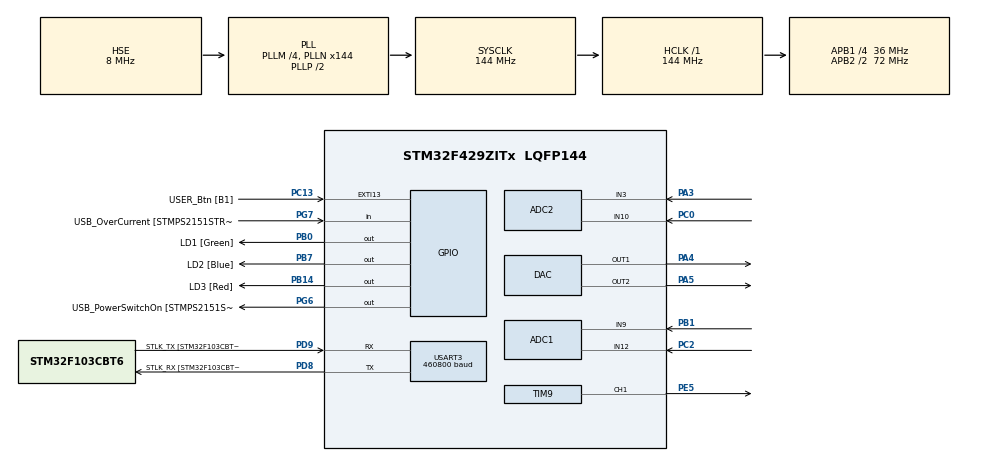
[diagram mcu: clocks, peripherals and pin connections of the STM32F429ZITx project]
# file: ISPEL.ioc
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ADC1.Channel-0\#ChannelRegularConversion=ADC_CHANNEL_9
ADC1.DMAAccessMode=ADC_DMAACCESSMODE_2
ADC1.DMAContinuousRequests=ENABLE
ADC1.EOCSelection=ADC_EOC_SEQ_CONV
ADC1.ExternalTrigConv=ADC_EXTERNALTRIGCONV_T3_TRGO
ADC1.Mode=ADC_DUALMODE_REGSIMULT
ADC1.NbrOfConversionFlag=1
ADC1.Rank-0\#ChannelRegularConversion=1
ADC1.SamplingTime-0\#ChannelRegularConversion=ADC_SAMPLETIME_3CYCLES
ADC1.master=1
ADC2.Channel-0\#ChannelRegularConversion=ADC_CHANNEL_3
ADC2.DMAAccessMode=ADC_DMAACCESSMODE_2
ADC2.DMAContinuousRequests=ENABLE
ADC2.EOCSelection=ADC_EOC_SEQ_CONV
ADC2.Mode=ADC_DUALMODE_REGSIMULT
ADC2.NbrOfConversionFlag=1
ADC2.Rank-0\#ChannelRegularConversion=1
ADC2.SamplingTime-0\#ChannelRegularConversion=ADC_SAMPLETIME_3CYCLES
DAC.DAC_Trigger=DAC_TRIGGER_T4_TRGO
DAC.DAC_Trigger2=DAC_TRIGGER_T2_TRGO
Dma.ADC1.0.Direction=DMA_PERIPH_TO_MEMORY
Dma.ADC1.0.FIFOMode=DMA_FIFOMODE_DISABLE
Dma.ADC1.0.Instance=DMA2_Stream0
Dma.ADC1.0.MemDataAlignment=DMA_MDATAALIGN_WORD
Dma.ADC1.0.MemInc=DMA_MINC_ENABLE
Dma.ADC1.0.Mode=DMA_CIRCULAR
Dma.ADC1.0.PeriphDataAlignment=DMA_PDATAALIGN_WORD
Dma.ADC1.0.PeriphInc=DMA_PINC_DISABLE
Dma.ADC1.0.Priority=DMA_PRIORITY_HIGH
Dma.ADC2.1.Direction=DMA_PERIPH_TO_MEMORY
Dma.ADC2.1.FIFOMode=DMA_FIFOMODE_DISABLE
Dma.ADC2.1.Instance=DMA2_Stream2
Dma.ADC2.1.MemDataAlignment=DMA_MDATAALIGN_WORD
Dma.ADC2.1.MemInc=DMA_MINC_ENABLE
Dma.ADC2.1.Mode=DMA_CIRCULAR
Dma.ADC2.1.PeriphDataAlignment=DMA_PDATAALIGN_WORD
Dma.ADC2.1.PeriphInc=DMA_PINC_DISABLE
Dma.ADC2.1.Priority=DMA_PRIORITY_HIGH
Dma.DAC1.2.Direction=DMA_MEMORY_TO_PERIPH
Dma.DAC1.2.FIFOMode=DMA_FIFOMODE_DISABLE
Dma.DAC1.2.Instance=DMA1_Stream5
Dma.DAC1.2.MemDataAlignment=DMA_MDATAALIGN_WORD
Dma.DAC1.2.MemInc=DMA_MINC_ENABLE
Dma.DAC1.2.Mode=DMA_CIRCULAR
Dma.DAC1.2.PeriphDataAlignment=DMA_PDATAALIGN_WORD
Dma.DAC1.2.PeriphInc=DMA_PINC_DISABLE
Dma.DAC1.2.Priority=DMA_PRIORITY_VERY_HIGH
Dma.DAC2.3.Direction=DMA_MEMORY_TO_PERIPH
Dma.DAC2.3.FIFOMode=DMA_FIFOMODE_DISABLE
Dma.DAC2.3.Instance=DMA1_Stream6
Dma.DAC2.3.MemDataAlignment=DMA_MDATAALIGN_WORD
Dma.DAC2.3.MemInc=DMA_MINC_ENABLE
Dma.DAC2.3.Mode=DMA_CIRCULAR
Dma.DAC2.3.PeriphDataAlignment=DMA_PDATAALIGN_WORD
Dma.DAC2.3.PeriphInc=DMA_PINC_DISABLE
Dma.DAC2.3.Priority=DMA_PRIORITY_VERY_HIGH
Dma.Request0=ADC1
Dma.Request1=ADC2
Dma.Request2=DAC1
Dma.Request3=DAC2
FREERTOS.INCLUDE_vTaskDelayUntil=1
FREERTOS.Tasks01=defaultTask,0,128,StartDefaultTask,Default,NULL,Dynamic,NULL,NULL
FREERTOS.configUSE_NEWLIB_REENTRANT=1
FREERTOS.configUSE_TIMERS=0
Mcu.Family=STM32F4
Mcu.Name=STM32F429ZITx
Mcu.Package=LQFP144
NVIC.ADC_IRQn=true\:5\:0\:false\:false\:true\:true\:true\:true\:true
NVIC.DMA1_Stream5_IRQn=true\:5\:0\:false\:false\:true\:true\:false\:true\:true
NVIC.DMA1_Stream6_IRQn=true\:5\:0\:false\:false\:true\:true\:false\:true\:true
NVIC.DMA2_Stream0_IRQn=true\:5\:0\:false\:false\:true\:true\:false\:true\:true
NVIC.DMA2_Stream2_IRQn=true\:5\:0\:false\:false\:true\:true\:false\:true\:true
NVIC.EXTI15_10_IRQn=true\:5\:0\:true\:false\:true\:true\:true\:true\:true
NVIC.PriorityGroup=NVIC_PRIORITYGROUP_4
NVIC.TIM7_IRQn=true\:15\:0\:false\:false\:true\:false\:false\:true\:true
NVIC.TimeBase=TIM7_IRQn
NVIC.TimeBaseIP=TIM7
PA1.GPIO_Label=RMII_REF_CLK [LAN8742A-CZ-TR_REFCLK0]
PA1.Signal=ETH_REF_CLK
PA10.GPIO_Label=USB_ID
PA10.Signal=USB_OTG_FS_ID
PA11.GPIO_Label=USB_DM
PA11.Signal=USB_OTG_FS_DM
PA12.GPIO_Label=USB_DP
PA12.Signal=USB_OTG_FS_DP
PA13.GPIO_Label=TMS
PA13.Mode=Serial_Wire
PA13.Signal=SYS_JTMS-SWDIO
PA14.GPIO_Label=TCK
PA14.Mode=Serial_Wire
PA14.Signal=SYS_JTCK-SWCLK
PA2.GPIO_Label=RMII_MDIO [LAN8742A-CZ-TR_MDIO]
PA2.Signal=ETH_MDIO
PA3.Signal=ADCx_IN3
PA4.Signal=COMP_DAC1_group
PA5.Signal=COMP_DAC2_group
PA7.GPIO_Label=RMII_CRS_DV [LAN8742A-CZ-TR_CRS_DV]
PA7.Signal=ETH_CRS_DV
PA8.GPIO_Label=USB_SOF [TP1]
PA8.Signal=USB_OTG_FS_SOF
PA9.GPIO_Label=USB_VBUS
PA9.Signal=USB_OTG_FS_VBUS
PB0.GPIO_Label=LD1 [Green]
PB0.Signal=GPIO_Output
PB1.Signal=ADCx_IN9
PB13.GPIO_Label=RMII_TXD1 [LAN8742A-CZ-TR_TXD1]
PB13.Signal=ETH_TXD1
PB14.GPIO_Label=LD3 [Red]
PB14.Signal=GPIO_Output
PB7.GPIO_Label=LD2 [Blue]
PB7.Signal=GPIO_Output
PC0.Signal=ADCx_IN10
PC1.GPIO_Label=RMII_MDC [LAN8742A-CZ-TR_MDC]
PC1.Signal=ETH_MDC
PC13.GPIO_Label=USER_Btn [B1]
PC13.GPIO_ModeDefaultEXTI=GPIO_MODE_IT_FALLING
PC13.Signal=GPXTI13
PC14/OSC32_IN.Mode=LSE-External-Oscillator
PC14/OSC32_IN.Signal=RCC_OSC32_IN
PC15/OSC32_OUT.Mode=LSE-External-Oscillator
PC15/OSC32_OUT.Signal=RCC_OSC32_OUT
PC2.Signal=ADCx_IN12
PC4.GPIO_Label=RMII_RXD0 [LAN8742A-CZ-TR_RXD0]
PC4.Signal=ETH_RXD0
PC5.GPIO_Label=RMII_RXD1 [LAN8742A-CZ-TR_RXD1]
PC5.Signal=ETH_RXD1
PD8.GPIO_Label=STLK_RX [STM32F103CBT6_PA3]
PD8.Mode=Asynchronous
PD8.Signal=USART3_TX
PD9.GPIO_Label=STLK_TX [STM32F103CBT6_PA2]
PD9.Mode=Asynchronous
PD9.Signal=USART3_RX
PE5.Signal=S_TIM9_CH1
PG11.GPIO_Label=RMII_TX_EN [LAN8742A-CZ-TR_TXEN]
PG11.Signal=ETH_TX_EN
PG13.GPIO_Label=RMII_TXD0 [LAN8742A-CZ-TR_TXD0]
PG13.Signal=ETH_TXD0
PG6.GPIO_Label=USB_PowerSwitchOn [STMPS2151STR_EN]
PG6.Signal=GPIO_Output
PG7.GPIO_Label=USB_OverCurrent [STMPS2151STR_FAULT]
PG7.Signal=GPIO_Input
PH0/OSC_IN.GPIO_Label=MCO [STM32F103CBT6_PA8]
PH0/OSC_IN.Mode=HSE-External-Clock-Source
PH0/OSC_IN.Signal=RCC_OSC_IN
PH1/OSC_OUT.Mode=HSE-External-Clock-Source
PH1/OSC_OUT.Signal=RCC_OSC_OUT
ProjectManager.HeapSize=0x200
ProjectManager.StackSize=0x400
ProjectManager.TargetToolchain=STM32CubeIDE
RCC.48MHZClocksFreq_Value=48000000
RCC.AHBFreq_Value=144000000
RCC.APB1CLKDivider=RCC_HCLK_DIV4
RCC.APB1Freq_Value=36000000
RCC.APB1TimFreq_Value=72000000
RCC.APB2CLKDivider=RCC_HCLK_DIV2
RCC.APB2Freq_Value=72000000
RCC.APB2TimCLKDivider=2
RCC.APB2TimFreq_Value=144000000
RCC.CortexFreq_Value=144000000
RCC.HCLKFreq_Value=144000000
RCC.HSE_VALUE=8000000
RCC.HSI_VALUE=16000000
RCC.PLLM=4
RCC.PLLMUL=RCC_PLL_MUL9
RCC.PLLN=144
RCC.PLLQ=6
RCC.PLLSourceVirtual=RCC_PLLSOURCE_HSE
RCC.PRESCALERUSB=RCC_USBCLKSOURCE_PLL_DIV1_5
RCC.SYSCLKFreq_VALUE=144000000
RCC.SYSCLKSource=RCC_SYSCLKSOURCE_PLLCLK
RCC.SYSCLKSourceVirtual=RCC_SYSCLKSOURCE_PLLCLK
RCC.USBFreq_Value=48000000
RCC.VCOOutputFreq_Value=288000000
SH.ADCx_IN10.0=ADC2_IN10,IN10
SH.ADCx_IN12.0=ADC1_IN12,IN12
SH.ADCx_IN3.0=ADC2_IN3,IN3
SH.ADCx_IN9.0=ADC1_IN9,IN9
SH.COMP_DAC1_group.0=DAC_OUT1,DAC_OUT1
SH.COMP_DAC2_group.0=DAC_OUT2,DAC_OUT2
SH.S_TIM9_CH1.0=TIM9_CH1,PWM Generation1 CH1
TIM9.Channel-PWM\ Generation1\ CH1=TIM_CHANNEL_1
USART3.BaudRate=460800
USART3.VirtualMode=VM_ASYNC
VP_FREERTOS_VS_CMSIS_V1.Mode=CMSIS_V1
VP_SYS_VS_tim7.Mode=TIM7
VP_TIM2_VS_ClockSourceINT.Mode=Internal
VP_TIM3_VS_ClockSourceINT.Mode=Internal
VP_TIM4_VS_ClockSourceINT.Mode=Internal
VP_TIM5_VS_ClockSourceINT.Mode=Internal
VP_TIM9_VS_ClockSourceINT.Mode=Internal
board=NUCLEO-F429ZI

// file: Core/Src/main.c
/* USER CODE BEGIN Header */
/**
  ******************************************************************************
  * @file           : main.c
  * @brief          : Cuerpo del programa principal autogenerado.
  *                   El código propio estará en otro archivo.
  ******************************************************************************
  * @attention
  *
  * Copyright (c) 2023 STMicroelectronics.
  * All rights reserved.
  *
  * This software is licensed under terms that can be found in the LICENSE file
  * in the root directory of this software component.
  * If no LICENSE file comes with this software, it is provided AS-IS.
  *
  ******************************************************************************
  */
/* USER CODE END Header */
#include "main.h"
#include "cmsis_os.h"

/* USER CODE BEGIN Includes */
#include "apli.h"

/* USER CODE END Includes */

ADC_HandleTypeDef hadc1;
ADC_HandleTypeDef hadc2;
DMA_HandleTypeDef hdma_adc1;
DMA_HandleTypeDef hdma_adc2;

DAC_HandleTypeDef hdac;
DMA_HandleTypeDef hdma_dac1;
DMA_HandleTypeDef hdma_dac2;

TIM_HandleTypeDef htim2;
TIM_HandleTypeDef htim3;
TIM_HandleTypeDef htim4;
TIM_HandleTypeDef htim5;
TIM_HandleTypeDef htim9;

UART_HandleTypeDef huart3;

osThreadId defaultTaskHandle;

void SystemClock_Config(void);
static void MX_GPIO_Init(void);
static void MX_DMA_Init(void);
static void MX_USART3_UART_Init(void);
static void MX_DAC_Init(void);
static void MX_TIM9_Init(void);
static void MX_TIM5_Init(void);
static void MX_ADC1_Init(void);
static void MX_ADC2_Init(void);
static void MX_TIM3_Init(void);
static void MX_TIM2_Init(void);
static void MX_TIM4_Init(void);
void StartDefaultTask(void const * argument);

int main(void)
{

  /* MCU Configuration--------------------------------------------------------*/

  /* Reset of all peripherals, Initializes the Flash interface and the Systick. */
  HAL_Init();

  /* Configure the system clock */
  SystemClock_Config();

  /* Initialize all configured peripherals */
  MX_GPIO_Init();
  MX_DMA_Init();
  MX_USART3_UART_Init();
  MX_DAC_Init();
  MX_TIM9_Init();
  MX_TIM5_Init();
  MX_ADC1_Init();
  MX_ADC2_Init();
  MX_TIM3_Init();
  MX_TIM2_Init();
  MX_TIM4_Init();
  /* USER CODE BEGIN 2 */
  /* ----------------------------------------------------------------------------------------------
   * Este llamado sirve para codear el programa en otro archivo.
   * Creamos una carpeta App, con sus respectivas subcarpetas.
   * ---------------------------------------------------------------------------------------------*/
  apli_inicializar();

  /* USER CODE END 2 */

  /* Create the thread(s) */
  /* definition and creation of defaultTask */
  osThreadDef(defaultTask, StartDefaultTask, osPriorityNormal, 0, 128);
  defaultTaskHandle = osThreadCreate(osThread(defaultTask), NULL);

  /* Start scheduler */
  osKernelStart();

  /* We should never get here as control is now taken by the scheduler */
  /* Infinite loop */
  while (1)
  {

  }
}

void SystemClock_Config(void)
{
  RCC_OscInitTypeDef RCC_OscInitStruct = {0};
  RCC_ClkInitTypeDef RCC_ClkInitStruct = {0};

  /** Configure the main internal regulator output voltage
  */
  __HAL_RCC_PWR_CLK_ENABLE();
  __HAL_PWR_VOLTAGESCALING_CONFIG(PWR_REGULATOR_VOLTAGE_SCALE1);

  /** Initializes the RCC Oscillators according to the specified parameters
  * in the RCC_OscInitTypeDef structure.
  */
  RCC_OscInitStruct.OscillatorType = RCC_OSCILLATORTYPE_HSE;
  RCC_OscInitStruct.HSEState = RCC_HSE_BYPASS;
  RCC_OscInitStruct.PLL.PLLState = RCC_PLL_ON;
  RCC_OscInitStruct.PLL.PLLSource = RCC_PLLSOURCE_HSE;
  RCC_OscInitStruct.PLL.PLLM = 4;
  RCC_OscInitStruct.PLL.PLLN = 144;
  RCC_OscInitStruct.PLL.PLLP = RCC_PLLP_DIV2;
  RCC_OscInitStruct.PLL.PLLQ = 6;
  if (HAL_RCC_OscConfig(&RCC_OscInitStruct) != HAL_OK)
  {
    Error_Handler();
  }

  /** Initializes the CPU, AHB and APB buses clocks
  */
  RCC_ClkInitStruct.ClockType = RCC_CLOCKTYPE_HCLK|RCC_CLOCKTYPE_SYSCLK
                              |RCC_CLOCKTYPE_PCLK1|RCC_CLOCKTYPE_PCLK2;
  RCC_ClkInitStruct.SYSCLKSource = RCC_SYSCLKSOURCE_PLLCLK;
  RCC_ClkInitStruct.AHBCLKDivider = RCC_SYSCLK_DIV1;
  RCC_ClkInitStruct.APB1CLKDivider = RCC_HCLK_DIV4;
  RCC_ClkInitStruct.APB2CLKDivider = RCC_HCLK_DIV2;

  if (HAL_RCC_ClockConfig(&RCC_ClkInitStruct, FLASH_LATENCY_4) != HAL_OK)
  {
    Error_Handler();
  }
}

static void MX_ADC1_Init(void)
{

  /* USER CODE BEGIN ADC1_Init 0 */

  return;

  /* USER CODE END ADC1_Init 0 */

  ADC_MultiModeTypeDef multimode = {0};
  ADC_ChannelConfTypeDef sConfig = {0};

  /** Configure the global features of the ADC (Clock, Resolution, Data Alignment and number of conversion)
  */
  hadc1.Instance = ADC1;
  hadc1.Init.ClockPrescaler = ADC_CLOCK_SYNC_PCLK_DIV2;
  hadc1.Init.Resolution = ADC_RESOLUTION_12B;
  hadc1.Init.ScanConvMode = DISABLE;
  hadc1.Init.ContinuousConvMode = DISABLE;
  hadc1.Init.DiscontinuousConvMode = DISABLE;
  hadc1.Init.ExternalTrigConvEdge = ADC_EXTERNALTRIGCONVEDGE_RISING;
  hadc1.Init.ExternalTrigConv = ADC_EXTERNALTRIGCONV_T3_TRGO;
  hadc1.Init.DataAlign = ADC_DATAALIGN_RIGHT;
  hadc1.Init.NbrOfConversion = 1;
  hadc1.Init.DMAContinuousRequests = ENABLE;
  hadc1.Init.EOCSelection = ADC_EOC_SEQ_CONV;
  if (HAL_ADC_Init(&hadc1) != HAL_OK)
  {
    Error_Handler();
  }

  /** Configure the ADC multi-mode
  */
  multimode.Mode = ADC_DUALMODE_REGSIMULT;
  multimode.DMAAccessMode = ADC_DMAACCESSMODE_2;
  multimode.TwoSamplingDelay = ADC_TWOSAMPLINGDELAY_5CYCLES;
  if (HAL_ADCEx_MultiModeConfigChannel(&hadc1, &multimode) != HAL_OK)
  {
    Error_Handler();
  }

  /** Configure for the selected ADC regular channel its corresponding rank in the sequencer and its sample time.
  */
  sConfig.Channel = ADC_CHANNEL_9;
  sConfig.Rank = 1;
  sConfig.SamplingTime = ADC_SAMPLETIME_3CYCLES;
  if (HAL_ADC_ConfigChannel(&hadc1, &sConfig) != HAL_OK)
  {
    Error_Handler();
  }

}

static void MX_ADC2_Init(void)
{

  /* USER CODE BEGIN ADC2_Init 0 */

  return;

  /* USER CODE END ADC2_Init 0 */

  ADC_ChannelConfTypeDef sConfig = {0};

  /** Configure the global features of the ADC (Clock, Resolution, Data Alignment and number of conversion)
  */
  hadc2.Instance = ADC2;
  hadc2.Init.ClockPrescaler = ADC_CLOCK_SYNC_PCLK_DIV2;
  hadc2.Init.Resolution = ADC_RESOLUTION_12B;
  hadc2.Init.ScanConvMode = DISABLE;
  hadc2.Init.ContinuousConvMode = DISABLE;
  hadc2.Init.DiscontinuousConvMode = DISABLE;
  hadc2.Init.DataAlign = ADC_DATAALIGN_RIGHT;
  hadc2.Init.NbrOfConversion = 1;
  hadc2.Init.DMAContinuousRequests = ENABLE;
  hadc2.Init.EOCSelection = ADC_EOC_SEQ_CONV;
  if (HAL_ADC_Init(&hadc2) != HAL_OK)
  {
    Error_Handler();
  }

  /** Configure for the selected ADC regular channel its corresponding rank in the sequencer and its sample time.
  */
  sConfig.Channel = ADC_CHANNEL_3;
  sConfig.Rank = 1;
  sConfig.SamplingTime = ADC_SAMPLETIME_3CYCLES;
  if (HAL_ADC_ConfigChannel(&hadc2, &sConfig) != HAL_OK)
  {
    Error_Handler();
  }

}

static void MX_DAC_Init(void)
{

  DAC_ChannelConfTypeDef sConfig = {0};

  /** DAC Initialization
  */
  hdac.Instance = DAC;
  if (HAL_DAC_Init(&hdac) != HAL_OK)
  {
    Error_Handler();
  }

  /** DAC channel OUT1 config
  */
  sConfig.DAC_Trigger = DAC_TRIGGER_T4_TRGO;
  sConfig.DAC_OutputBuffer = DAC_OUTPUTBUFFER_ENABLE;
  if (HAL_DAC_ConfigChannel(&hdac, &sConfig, DAC_CHANNEL_1) != HAL_OK)
  {
    Error_Handler();
  }

  /** DAC channel OUT2 config
  */
  sConfig.DAC_Trigger = DAC_TRIGGER_T2_TRGO;
  if (HAL_DAC_ConfigChannel(&hdac, &sConfig, DAC_CHANNEL_2) != HAL_OK)
  {
    Error_Handler();
  }

}

static void MX_TIM2_Init(void)
{

  TIM_ClockConfigTypeDef sClockSourceConfig = {0};
  TIM_MasterConfigTypeDef sMasterConfig = {0};

  htim2.Instance = TIM2;
  htim2.Init.Prescaler = 0;
  htim2.Init.CounterMode = TIM_COUNTERMODE_UP;
  htim2.Init.Period = 4294967295;
  htim2.Init.ClockDivision = TIM_CLOCKDIVISION_DIV1;
  htim2.Init.AutoReloadPreload = TIM_AUTORELOAD_PRELOAD_DISABLE;
  if (HAL_TIM_Base_Init(&htim2) != HAL_OK)
  {
    Error_Handler();
  }
  sClockSourceConfig.ClockSource = TIM_CLOCKSOURCE_INTERNAL;
  if (HAL_TIM_ConfigClockSource(&htim2, &sClockSourceConfig) != HAL_OK)
  {
    Error_Handler();
  }
  sMasterConfig.MasterOutputTrigger = TIM_TRGO_RESET;
  sMasterConfig.MasterSlaveMode = TIM_MASTERSLAVEMODE_DISABLE;
  if (HAL_TIMEx_MasterConfigSynchronization(&htim2, &sMasterConfig) != HAL_OK)
  {
    Error_Handler();
  }

}

static void MX_TIM3_Init(void)
{

  /* USER CODE BEGIN TIM3_Init 0 */

  return;

  /* USER CODE END TIM3_Init 0 */

  TIM_ClockConfigTypeDef sClockSourceConfig = {0};
  TIM_MasterConfigTypeDef sMasterConfig = {0};

  htim3.Instance = TIM3;
  htim3.Init.Prescaler = 0;
  htim3.Init.CounterMode = TIM_COUNTERMODE_UP;
  htim3.Init.Period = 65535;
  htim3.Init.ClockDivision = TIM_CLOCKDIVISION_DIV1;
  htim3.Init.AutoReloadPreload = TIM_AUTORELOAD_PRELOAD_DISABLE;
  if (HAL_TIM_Base_Init(&htim3) != HAL_OK)
  {
    Error_Handler();
  }
  sClockSourceConfig.ClockSource = TIM_CLOCKSOURCE_INTERNAL;
  if (HAL_TIM_ConfigClockSource(&htim3, &sClockSourceConfig) != HAL_OK)
  {
    Error_Handler();
  }
  sMasterConfig.MasterOutputTrigger = TIM_TRGO_RESET;
  sMasterConfig.MasterSlaveMode = TIM_MASTERSLAVEMODE_DISABLE;
  if (HAL_TIMEx_MasterConfigSynchronization(&htim3, &sMasterConfig) != HAL_OK)
  {
    Error_Handler();
  }

}

static void MX_TIM4_Init(void)
{

  TIM_ClockConfigTypeDef sClockSourceConfig = {0};
  TIM_MasterConfigTypeDef sMasterConfig = {0};

  htim4.Instance = TIM4;
  htim4.Init.Prescaler = 0;
  htim4.Init.CounterMode = TIM_COUNTERMODE_UP;
  htim4.Init.Period = 65535;
  htim4.Init.ClockDivision = TIM_CLOCKDIVISION_DIV1;
  htim4.Init.AutoReloadPreload = TIM_AUTORELOAD_PRELOAD_DISABLE;
  if (HAL_TIM_Base_Init(&htim4) != HAL_OK)
  {
    Error_Handler();
  }
  sClockSourceConfig.ClockSource = TIM_CLOCKSOURCE_INTERNAL;
  if (HAL_TIM_ConfigClockSource(&htim4, &sClockSourceConfig) != HAL_OK)
  {
    Error_Handler();
  }
  sMasterConfig.MasterOutputTrigger = TIM_TRGO_RESET;
  sMasterConfig.MasterSlaveMode = TIM_MASTERSLAVEMODE_DISABLE;
  if (HAL_TIMEx_MasterConfigSynchronization(&htim4, &sMasterConfig) != HAL_OK)
  {
    Error_Handler();
  }

}

static void MX_TIM5_Init(void)
{

  /* USER CODE BEGIN TIM5_Init 0 */

  return;

  /* USER CODE END TIM5_Init 0 */

  TIM_ClockConfigTypeDef sClockSourceConfig = {0};
  TIM_MasterConfigTypeDef sMasterConfig = {0};

  htim5.Instance = TIM5;
  htim5.Init.Prescaler = 0;
  htim5.Init.CounterMode = TIM_COUNTERMODE_UP;
  htim5.Init.Period = 4294967295;
  htim5.Init.ClockDivision = TIM_CLOCKDIVISION_DIV1;
  htim5.Init.AutoReloadPreload = TIM_AUTORELOAD_PRELOAD_DISABLE;
  if (HAL_TIM_Base_Init(&htim5) != HAL_OK)
  {
    Error_Handler();
  }
  sClockSourceConfig.ClockSource = TIM_CLOCKSOURCE_INTERNAL;
  if (HAL_TIM_ConfigClockSource(&htim5, &sClockSourceConfig) != HAL_OK)
  {
    Error_Handler();
  }
  sMasterConfig.MasterOutputTrigger = TIM_TRGO_RESET;
  sMasterConfig.MasterSlaveMode = TIM_MASTERSLAVEMODE_DISABLE;
  if (HAL_TIMEx_MasterConfigSynchronization(&htim5, &sMasterConfig) != HAL_OK)
  {
    Error_Handler();
  }

}

static void MX_TIM9_Init(void)
{

  /* USER CODE BEGIN TIM9_Init 0 */

  // Funcion boba para habilitar librería específica
  return;

  /* USER CODE END TIM9_Init 0 */

  TIM_ClockConfigTypeDef sClockSourceConfig = {0};
  TIM_OC_InitTypeDef sConfigOC = {0};

  htim9.Instance = TIM9;
  htim9.Init.Prescaler = 0;
  htim9.Init.CounterMode = TIM_COUNTERMODE_UP;
  htim9.Init.Period = 65535;
  htim9.Init.ClockDivision = TIM_CLOCKDIVISION_DIV1;
  htim9.Init.AutoReloadPreload = TIM_AUTORELOAD_PRELOAD_DISABLE;
  if (HAL_TIM_Base_Init(&htim9) != HAL_OK)
  {
    Error_Handler();
  }
  sClockSourceConfig.ClockSource = TIM_CLOCKSOURCE_INTERNAL;
  if (HAL_TIM_ConfigClockSource(&htim9, &sClockSourceConfig) != HAL_OK)
  {
    Error_Handler();
  }
  if (HAL_TIM_PWM_Init(&htim9) != HAL_OK)
  {
    Error_Handler();
  }
  sConfigOC.OCMode = TIM_OCMODE_PWM1;
  sConfigOC.Pulse = 0;
  sConfigOC.OCPolarity = TIM_OCPOLARITY_HIGH;
  sConfigOC.OCFastMode = TIM_OCFAST_DISABLE;
  if (HAL_TIM_PWM_ConfigChannel(&htim9, &sConfigOC, TIM_CHANNEL_1) != HAL_OK)
  {
    Error_Handler();
  }
  HAL_TIM_MspPostInit(&htim9);

}

static void MX_USART3_UART_Init(void)
{

  /* USER CODE BEGIN USART3_Init 0 */

  // Función tonta para que CubeMX habilite librerías <--------------------------------------------
  return;

  /* USER CODE END USART3_Init 0 */

  huart3.Instance = USART3;
  huart3.Init.BaudRate = 460800;
  huart3.Init.WordLength = UART_WORDLENGTH_8B;
  huart3.Init.StopBits = UART_STOPBITS_1;
  huart3.Init.Parity = UART_PARITY_NONE;
  huart3.Init.Mode = UART_MODE_TX_RX;
  huart3.Init.HwFlowCtl = UART_HWCONTROL_NONE;
  huart3.Init.OverSampling = UART_OVERSAMPLING_16;
  if (HAL_UART_Init(&huart3) != HAL_OK)
  {
    Error_Handler();
  }

}

static void MX_DMA_Init(void)
{

  /* DMA controller clock enable */
  __HAL_RCC_DMA2_CLK_ENABLE();
  __HAL_RCC_DMA1_CLK_ENABLE();

  /* DMA interrupt init */
  /* DMA1_Stream5_IRQn interrupt configuration */
  HAL_NVIC_SetPriority(DMA1_Stream5_IRQn, 5, 0);
  HAL_NVIC_EnableIRQ(DMA1_Stream5_IRQn);
  /* DMA1_Stream6_IRQn interrupt configuration */
  HAL_NVIC_SetPriority(DMA1_Stream6_IRQn, 5, 0);
  HAL_NVIC_EnableIRQ(DMA1_Stream6_IRQn);
  /* DMA2_Stream0_IRQn interrupt configuration */
  HAL_NVIC_SetPriority(DMA2_Stream0_IRQn, 5, 0);
  HAL_NVIC_EnableIRQ(DMA2_Stream0_IRQn);
  /* DMA2_Stream2_IRQn interrupt configuration */
  HAL_NVIC_SetPriority(DMA2_Stream2_IRQn, 5, 0);
  HAL_NVIC_EnableIRQ(DMA2_Stream2_IRQn);

}

static void MX_GPIO_Init(void)
{
  GPIO_InitTypeDef GPIO_InitStruct = {0};

  /* GPIO Ports Clock Enable */
  __HAL_RCC_GPIOE_CLK_ENABLE();
  __HAL_RCC_GPIOC_CLK_ENABLE();
  __HAL_RCC_GPIOH_CLK_ENABLE();
  __HAL_RCC_GPIOA_CLK_ENABLE();
  __HAL_RCC_GPIOB_CLK_ENABLE();
  __HAL_RCC_GPIOD_CLK_ENABLE();
  __HAL_RCC_GPIOG_CLK_ENABLE();

  /*Configure GPIO pin Output Level */
  HAL_GPIO_WritePin(GPIOB, LD1_Pin|LD3_Pin|LD2_Pin, GPIO_PIN_RESET);

  /*Configure GPIO pin Output Level */
  HAL_GPIO_WritePin(USB_PowerSwitchOn_GPIO_Port, USB_PowerSwitchOn_Pin, GPIO_PIN_RESET);

  /*Configure GPIO pin : USER_Btn_Pin */
  GPIO_InitStruct.Pin = USER_Btn_Pin;
  GPIO_InitStruct.Mode = GPIO_MODE_IT_FALLING;
  GPIO_InitStruct.Pull = GPIO_NOPULL;
  HAL_GPIO_Init(USER_Btn_GPIO_Port, &GPIO_InitStruct);

  /*Configure GPIO pins : RMII_MDC_Pin RMII_RXD0_Pin RMII_RXD1_Pin */
  GPIO_InitStruct.Pin = RMII_MDC_Pin|RMII_RXD0_Pin|RMII_RXD1_Pin;
  GPIO_InitStruct.Mode = GPIO_MODE_AF_PP;
  GPIO_InitStruct.Pull = GPIO_NOPULL;
  GPIO_InitStruct.Speed = GPIO_SPEED_FREQ_VERY_HIGH;
  GPIO_InitStruct.Alternate = GPIO_AF11_ETH;
  HAL_GPIO_Init(GPIOC, &GPIO_InitStruct);

  /*Configure GPIO pins : RMII_REF_CLK_Pin RMII_MDIO_Pin RMII_CRS_DV_Pin */
  GPIO_InitStruct.Pin = RMII_REF_CLK_Pin|RMII_MDIO_Pin|RMII_CRS_DV_Pin;
  GPIO_InitStruct.Mode = GPIO_MODE_AF_PP;
  GPIO_InitStruct.Pull = GPIO_NOPULL;
  GPIO_InitStruct.Speed = GPIO_SPEED_FREQ_VERY_HIGH;
  GPIO_InitStruct.Alternate = GPIO_AF11_ETH;
  HAL_GPIO_Init(GPIOA, &GPIO_InitStruct);

  /*Configure GPIO pins : LD1_Pin LD3_Pin LD2_Pin */
  GPIO_InitStruct.Pin = LD1_Pin|LD3_Pin|LD2_Pin;
  GPIO_InitStruct.Mode = GPIO_MODE_OUTPUT_PP;
  GPIO_InitStruct.Pull = GPIO_NOPULL;
  GPIO_InitStruct.Speed = GPIO_SPEED_FREQ_LOW;
  HAL_GPIO_Init(GPIOB, &GPIO_InitStruct);

  /*Configure GPIO pin : RMII_TXD1_Pin */
  GPIO_InitStruct.Pin = RMII_TXD1_Pin;
  GPIO_InitStruct.Mode = GPIO_MODE_AF_PP;
  GPIO_InitStruct.Pull = GPIO_NOPULL;
  GPIO_InitStruct.Speed = GPIO_SPEED_FREQ_VERY_HIGH;
  GPIO_InitStruct.Alternate = GPIO_AF11_ETH;
  HAL_GPIO_Init(RMII_TXD1_GPIO_Port, &GPIO_InitStruct);

  /*Configure GPIO pin : USB_PowerSwitchOn_Pin */
  GPIO_InitStruct.Pin = USB_PowerSwitchOn_Pin;
  GPIO_InitStruct.Mode = GPIO_MODE_OUTPUT_PP;
  GPIO_InitStruct.Pull = GPIO_NOPULL;
  GPIO_InitStruct.Speed = GPIO_SPEED_FREQ_LOW;
  HAL_GPIO_Init(USB_PowerSwitchOn_GPIO_Port, &GPIO_InitStruct);

  /*Configure GPIO pin : USB_OverCurrent_Pin */
  GPIO_InitStruct.Pin = USB_OverCurrent_Pin;
  GPIO_InitStruct.Mode = GPIO_MODE_INPUT;
  GPIO_InitStruct.Pull = GPIO_NOPULL;
  HAL_GPIO_Init(USB_OverCurrent_GPIO_Port, &GPIO_InitStruct);

  /*Configure GPIO pins : USB_SOF_Pin USB_ID_Pin USB_DM_Pin USB_DP_Pin */
  GPIO_InitStruct.Pin = USB_SOF_Pin|USB_ID_Pin|USB_DM_Pin|USB_DP_Pin;
  GPIO_InitStruct.Mode = GPIO_MODE_AF_PP;
  GPIO_InitStruct.Pull = GPIO_NOPULL;
  GPIO_InitStruct.Speed = GPIO_SPEED_FREQ_VERY_HIGH;
  GPIO_InitStruct.Alternate = GPIO_AF10_OTG_FS;
  HAL_GPIO_Init(GPIOA, &GPIO_InitStruct);

  /*Configure GPIO pin : USB_VBUS_Pin */
  GPIO_InitStruct.Pin = USB_VBUS_Pin;
  GPIO_InitStruct.Mode = GPIO_MODE_INPUT;
  GPIO_InitStruct.Pull = GPIO_NOPULL;
  HAL_GPIO_Init(USB_VBUS_GPIO_Port, &GPIO_InitStruct);

  /*Configure GPIO pins : RMII_TX_EN_Pin RMII_TXD0_Pin */
  GPIO_InitStruct.Pin = RMII_TX_EN_Pin|RMII_TXD0_Pin;
  GPIO_InitStruct.Mode = GPIO_MODE_AF_PP;
  GPIO_InitStruct.Pull = GPIO_NOPULL;
  GPIO_InitStruct.Speed = GPIO_SPEED_FREQ_VERY_HIGH;
  GPIO_InitStruct.Alternate = GPIO_AF11_ETH;
  HAL_GPIO_Init(GPIOG, &GPIO_InitStruct);

  /* EXTI interrupt init*/
  HAL_NVIC_SetPriority(EXTI15_10_IRQn, 5, 0);
  HAL_NVIC_EnableIRQ(EXTI15_10_IRQn);

}

void StartDefaultTask(void const * argument)
{
  for(;;)
  {
    osDelay(1);
  }
}

void HAL_TIM_PeriodElapsedCallback(TIM_HandleTypeDef *htim)
{
  /* USER CODE BEGIN Callback 0 */

  // ATENCION!!!
  // El CubeMX setea al TEMPO 7 para FreeRTOS <----------------------------------------------------

  /* USER CODE END Callback 0 */
  if (htim->Instance == TIM7) {
    HAL_IncTick();
  }
}

void Error_Handler(void)
{
  __disable_irq();
  while (1)
  {
  }
}
